# CY8C4245AXI_483 register map
File version: 0.1
PSoC 4200
Registers are 32-bit, read-write, no defined reset value unless marked. A register's access mark holds for its fields unless they carry their own. Offsets are from the block's base; lines under a group give offsets from that group; [hi:lo] are bit positions; {n}, {i} and the like mark numbered series; 'fields as' and 'values as' point back to an identical list; <NAME> marks a mode.

## Memory map
0x00000000 Opamp_2 — OpAmp
0x00000000 IDAC8 — IDAC
0x00000000 Opamp_1 — OpAmp
0x00000000 SamplingTimer

## Opamp_2 — OpAmp
Base 0x00000000
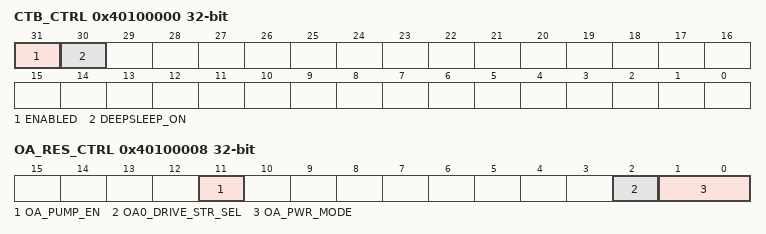
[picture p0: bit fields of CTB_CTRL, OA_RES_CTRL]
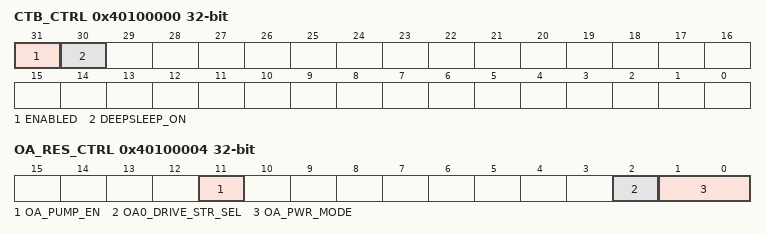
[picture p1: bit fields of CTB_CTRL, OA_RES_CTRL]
0x40100000 CTB_CTRL — Global CTB IP and power control
  [31] ENABLED — Selects component behavior in DeepSleep power mode
    0=DISABLE (CTB IP disabled (put analog in power down, open all switches)); 1=ENABLE (CTB IP enabledCTB IP enabled)
  [30] DEEPSLEEP_ON — Selects component behavior in DeepSleep power mode
    0=DISABLE (CTB IP disabled off during DeepSleep power mode); 1=ENABLE (CTB IP remains enabled during DeepSleep power mode (if ENABLED=1))
0x40100008 OA_RES_CTRL — Opamp and resistor control
  [11] OA_PUMP_EN — Selects pump
    0=DISABLE (Pump disabled); 1=ENABLE (Pump enabled)
  [2] OA0_DRIVE_STR_SEL — Opamp output strenght select
    0=Internal only; 1=Output to pin
  [1:0] OA_PWR_MODE — Selects power for opamp
    0=OFF; 1=LOW (Low power); 2=MED (Medium power); 3=HIGH (High power)
0x40100F14 OA_COMP_TRIM — Opamp Compenation Capacitor Trim
  [1:0] OA_COMP_TRIM
    1=HIGH_SPEED; 2=BALANCED; 3=HIGH_STABILITY

## IDAC8 — IDAC
Base 0x00000000
0x40080004 CSD_IDAC_POLARITY
0x40080008 CSD_IDAC
0x4008FF00 CSD_TRIM1 — CSD IDAC TRIM1
0x4008FF04 CSD_TRIM2 — CSD IDAC TRIM2

## Opamp_1 — OpAmp
Base 0x00000000
0x40100000 CTB_CTRL — Global CTB IP and power control
  fields as Opamp_2.CTB_CTRL
0x40100004 OA_RES_CTRL — Opamp and resistor control
  fields as Opamp_2.OA_RES_CTRL
0x40100F08 OA_COMP_TRIM — Opamp Compenation Capacitor Trim
  [1:0] OA_COMP_TRIM
    1=HIGH_SPEED; 2=BALANCED; 3=HIGH_STABILITY

## SamplingTimer
Base 0x00000000
0x40050108 COUNTER — Current counter value
0x4005010C CC — Compare / capture value
0x40050110 CC_BUF — Compare / capture buffer value
0x40050114 PERIOD — Period value
0x40050118 PERIOD_BUF — Period buffer value
